# PIC32CM5112SG00048 register map
Vendor: Microchip Technology; Series: PIC32CMSG00; File version: 0
CPU: CM23 r0p0, little endian, MPU, no FPU, 2 interrupt priority bits, 141 interrupts, 13 SAU regions
Registers are 32-bit, read-write, reset 0x0 unless marked. A register's access mark holds for its fields unless they carry their own. Offsets are from the block's base; [hi:lo] are bit positions; {n}, {i} and the like mark numbered series; 'fields as' and 'values as' point back to an identical list.

## AT — Anti-Tamper Controller (AT)
Base 0x4500C000
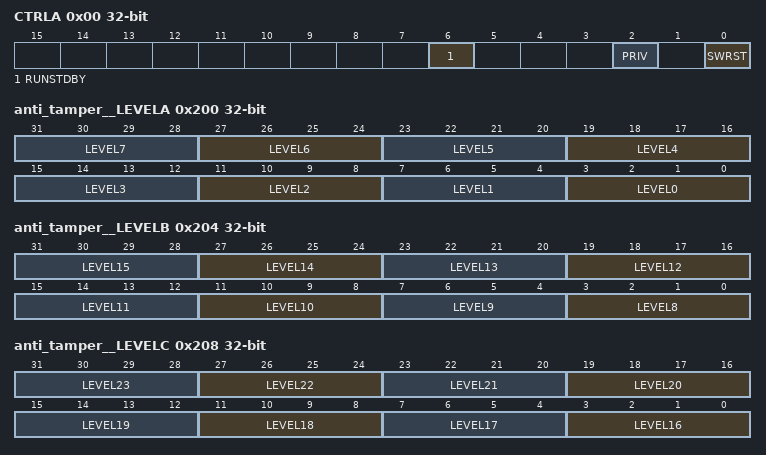
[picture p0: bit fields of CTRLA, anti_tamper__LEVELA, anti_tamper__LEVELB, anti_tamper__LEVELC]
0x00 CTRLA — Control Register A
  [6] RUNSTDBY — RUNSTDBY Enable Bit
  [2] PRIV — Privileged Access Only
    0=AT registers accessible in privileged and unprivileged modes; 1=AT registers only accessible in privileged mode
  [0] SWRST — Software Reset1 = Reset registers , Bus I/F and internal state0 = No effect
{0x100+4i} TAMPER_KEY[{i}] (i=0..15) — Tamper Key n Register
  [31:0] TAMPERKEY — Tamper Key Value
0x200 anti_tamper__LEVELA ro — Tamper levels 0 to 7.
  [4n+3:4n] LEVEL{n} (n=0..7)
0x204 anti_tamper__LEVELB ro — Tamper levels 8 to 15.
  [4n-29:4n-32] LEVEL{n} (n=8..15)
0x208 anti_tamper__LEVELC ro — Tamper levels 16 to 23.
  [4n-61:4n-64] LEVEL{n} (n=16..23)
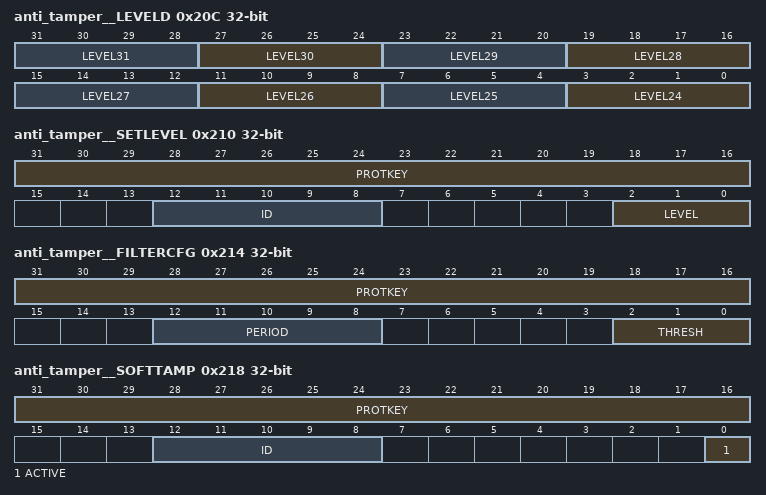
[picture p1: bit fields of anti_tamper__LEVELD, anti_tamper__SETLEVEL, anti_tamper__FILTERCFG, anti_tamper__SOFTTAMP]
0x20C anti_tamper__LEVELD ro — Tamper levels 24 to 31.
  [4n-93:4n-96] LEVEL{n} (n=24..31)
0x210 anti_tamper__SETLEVEL wo — Set tamper level.
  [31:16] PROTKEY — Protection key (0xA84C).
  [12:8] ID — Tamper ID.
  [2:0] LEVEL — Tamper level.
0x214 anti_tamper__FILTERCFG — Filter configuration (threshold, period).
  [31:16] PROTKEY — Protection key (0x92F5).
  [12:8] PERIOD
  [2:0] THRESH — Threshold.
0x218 anti_tamper__SOFTTAMP — Software triggered tamper.
  [31:16] PROTKEY — Protection key (0x4BEE).
  [12:8] ID — Tamper ID.
  [0] ACTIVE — Tamper active.
0x21C anti_tamper__RAWSTAT ro — Raw status.
0x220 anti_tamper__STAT reset 0x1 — Status (write to clear).
0x224 anti_tamper__TIMESTAMP ro — Timestamp for the last tamper.
0x228 anti_tamper__FILTERCNT ro — Current value of filter counter.
0x22C anti_tamper__SOFTINFO — Register for software purpose only.
0x230 anti_tamper__TAMPERFLAG — The 1-bit TAMPERFLAG register directly controls the TAMPER_FLAG output.
  [0] TAMPERFLAG
0x234 anti_tamper__SOFTRESET ro write-1-sets — Reading the SOFTLVL4 register returns 1 if any active soft tamper has a level of 4 or above.
  [0] SOFTRESET

## BROMC — ARM GF55LPx Boot ROM Controller Macro
Base 0x44804000
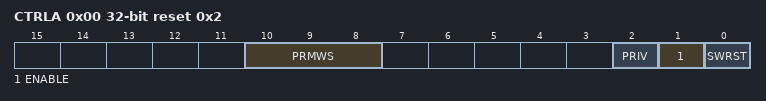
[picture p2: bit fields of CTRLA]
0x00 CTRLA reset 0x2 — Control A REGISTER
  [10:8] PRMWS — ROM Access Time Wait State
    0=No wait states, single cycle access; 1=Access time extended 2 clock cycles; 2=Access time extended to 3 clock cycles; 7=Access time extended to 8 clock cycles
  [2] PRIV — Privileged Access Only
    0=Macro register accessible in privileged and unprivileged modes; 1=Macro registers only accessible in privileged mode
  [1] ENABLE — Enable bit
    0=Disable ROM read access and power down the ROM. The ROM PGEN input is driven high. The ROM will clamp outputs to 1 and disable all internal current sinks. Refer to the ROM compiler specification for details on powering down the ROM.; 1=Enable ROM read access, power up the ROM. The ROM PGEN input is driven low.
  [0] SWRST — Software Reset bit
0x04 UCFG ro reset 0x1 — User Configuration REGISTER
  [0] BCRCDIS — Boot CRC Disable
    0=Boot ROM content is CRC verified by the ROM controller, status is reported to the DSU. On CRC failure, the controller blocks access to the ROM controller.; 1=No CRC verification at Boot

## CCL0 — Configurable Custom Logic
Base 0x4482E000; register names take the prefix CCL_
Same registers: CCL1 0x44830000
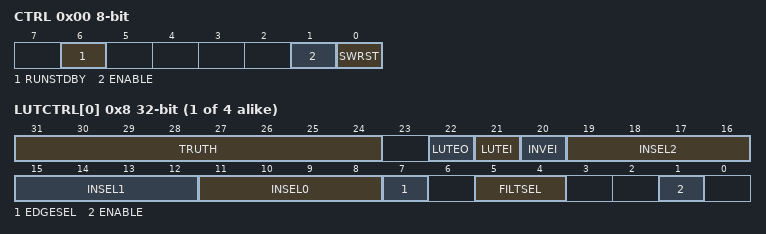
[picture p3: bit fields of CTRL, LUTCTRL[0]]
0x00 CTRL 8-bit — Control
  [6] RUNSTDBY — Run in Standby
    0=DISABLE (Generic clock is not required in standby sleep mode); 1=ENABLE (Generic clock is required in standby sleep mode)
  [1] ENABLE
    0=DISABLE (The peripheral is disabled); 1=ENABLE (The peripheral is enabled)
  [0] SWRST — Software Reset
    0=DISABLE (The peripheral is not reset); 1=ENABLE (The peripheral is reset)
{0x4+i} SEQCTRL[{i}] (i=0..1) 8-bit — SEQ Control x
  [3:0] SEQSEL — Sequential Selection
    0=DISABLE (Sequential logic is disabled); 1=DFF (D flip flop); 2=JK (JK flip flop); 3=LATCH (D latch); 4=RS (RS latch)
{0x8+4i} LUTCTRL[{i}] (i=0..3) — LUT Control x
  [31:24] TRUTH — Truth Value
  [22] LUTEO — LUT Event Output Enable
    0=DISABLE (LUT event output is disabled); 1=ENABLE (LUT event output is enabled)
  [21] LUTEI — LUT Event Input Enable
    0=DISABLE (LUT incoming event is disabled); 1=ENABLE (LUT incoming event is enabled)
  [20] INVEI — Inverted Event Input Enable
    0=NORMAL (Incoming event is not inverted); 1=INVERTED (Incoming event is inverted)
  [19:16] INSEL2 — Input Selection 2
    0=MASK (Masked input); 1=FEEDBACK (Feedback input source); 2=LINK (Linked LUT input source); 3=EVENT (Event input source); 4=IO (I/O pin input source); {v}=PERSEL{v-5} (Peripheral {v-5} input source) (v=5..10); 11=ASYNCEVENT (Asynchronous event input source. The EVENT input will bypass edge detection logic.)
  [15:12] INSEL1 — Input Selection 1
    values as INSEL2
  [11:8] INSEL0 — Input Selection 0
    values as INSEL2
  [7] EDGESEL — Edge Selection
    0=DISABLE (Edge detector is disabled); 1=ENABLE (Edge detector is enabled)
  [5:4] FILTSEL — Filter Selection
    0=DISABLE (Filter disabled); 1=SYNCH (Synchronizer enabled); 2=FILTER (Filter enabled)
  [1] ENABLE — LUT Enable
    0=DISABLE (LUT block is disabled); 1=ENABLE (LUT block is enabled)
